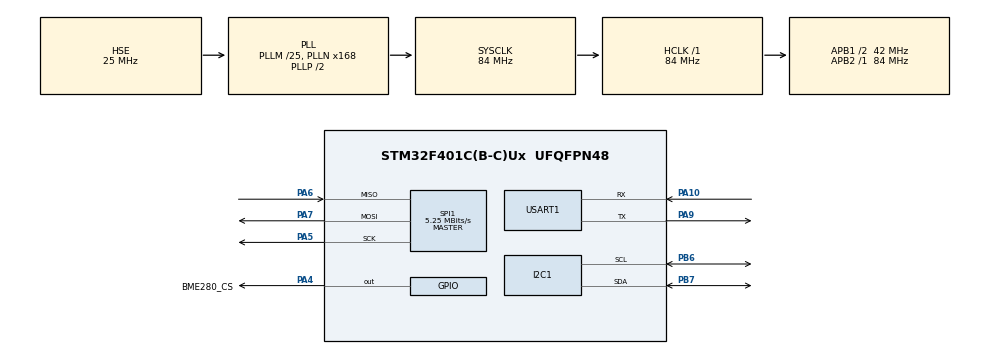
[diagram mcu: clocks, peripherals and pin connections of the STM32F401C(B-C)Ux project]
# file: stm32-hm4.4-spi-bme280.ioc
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FREERTOS.Tasks01=defaultTask,24,128,StartDefaultTask,Default,NULL,Dynamic,NULL,NULL
FREERTOS.configUSE_NEWLIB_REENTRANT=1
I2C1.I2C_Mode=I2C_Fast
Mcu.Family=STM32F4
Mcu.Name=STM32F401C(B-C)Ux
Mcu.Package=UFQFPN48
NVIC.PriorityGroup=NVIC_PRIORITYGROUP_4
NVIC.TIM1_UP_TIM10_IRQn=true\:15\:0\:false\:false\:true\:false\:false\:true\:true
NVIC.TimeBase=TIM1_UP_TIM10_IRQn
NVIC.TimeBaseIP=TIM1
PA10.Mode=Asynchronous
PA10.Signal=USART1_RX
PA13.Mode=Serial_Wire
PA13.Signal=SYS_JTMS-SWDIO
PA14.Mode=Serial_Wire
PA14.Signal=SYS_JTCK-SWCLK
PA4.GPIO_Label=BME280_CS
PA4.Signal=GPIO_Output
PA5.Mode=Full_Duplex_Master
PA5.Signal=SPI1_SCK
PA6.Mode=Full_Duplex_Master
PA6.Signal=SPI1_MISO
PA7.Mode=Full_Duplex_Master
PA7.Signal=SPI1_MOSI
PA9.Mode=Asynchronous
PA9.Signal=USART1_TX
PB6.Mode=I2C
PB6.Signal=I2C1_SCL
PB7.Mode=I2C
PB7.Signal=I2C1_SDA
PH0\ -\ OSC_IN.Mode=HSE-External-Oscillator
PH0\ -\ OSC_IN.Signal=RCC_OSC_IN
PH1\ -\ OSC_OUT.Mode=HSE-External-Oscillator
PH1\ -\ OSC_OUT.Signal=RCC_OSC_OUT
ProjectManager.HeapSize=0x200
ProjectManager.StackSize=0x400
ProjectManager.TargetToolchain=STM32CubeIDE
RCC.48MHZClocksFreq_Value=42000000
RCC.AHBFreq_Value=84000000
RCC.APB1CLKDivider=RCC_HCLK_DIV2
RCC.APB1Freq_Value=42000000
RCC.APB1TimFreq_Value=84000000
RCC.APB2Freq_Value=84000000
RCC.APB2TimFreq_Value=84000000
RCC.CortexFreq_Value=84000000
RCC.HCLKFreq_Value=84000000
RCC.HSE_VALUE=25000000
RCC.HSI_VALUE=16000000
RCC.LSE_VALUE=32768
RCC.PLLM=25
RCC.PLLN=168
RCC.PLLSourceVirtual=RCC_PLLSOURCE_HSE
RCC.SYSCLKFreq_VALUE=84000000
RCC.SYSCLKSource=RCC_SYSCLKSOURCE_PLLCLK
RCC.VCOOutputFreq_Value=168000000
SPI1.BaudRatePrescaler=SPI_BAUDRATEPRESCALER_16
SPI1.CalculateBaudRate=5.25 MBits/s
SPI1.Direction=SPI_DIRECTION_2LINES
SPI1.Mode=SPI_MODE_MASTER
SPI1.VirtualType=VM_MASTER
USART1.VirtualMode=VM_ASYNC
VP_FREERTOS_VS_CMSIS_V2.Mode=CMSIS_V2
VP_SYS_VS_tim1.Mode=TIM1
board=custom

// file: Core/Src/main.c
/* USER CODE BEGIN Header */
/**
  ******************************************************************************
  * @file           : main.c
  * @brief          : Main program body
  ******************************************************************************
  * @attention
  *
  * Copyright (c) 2026 STMicroelectronics.
  * All rights reserved.
  *
  * This software is licensed under terms that can be found in the LICENSE file
  * in the root directory of this software component.
  * If no LICENSE file comes with this software, it is provided AS-IS.
  *
  ******************************************************************************
  */
/* USER CODE END Header */
#include "main.h"
#include "cmsis_os.h"

/* USER CODE BEGIN Includes */
#include "app_main.h"
/* USER CODE END Includes */

I2C_HandleTypeDef hi2c1;

SPI_HandleTypeDef hspi1;

UART_HandleTypeDef huart1;

/* Definitions for defaultTask */
osThreadId_t defaultTaskHandle;
const osThreadAttr_t defaultTask_attributes = {
  .name = "defaultTask",
  .stack_size = 128 * 4,
  .priority = (osPriority_t) osPriorityNormal,
};

void SystemClock_Config(void);
static void MX_GPIO_Init(void);
static void MX_I2C1_Init(void);
static void MX_SPI1_Init(void);
static void MX_USART1_UART_Init(void);
void StartDefaultTask(void *argument);

/* USER CODE BEGIN 0 */
int __io_putchar(int ch) {
    HAL_UART_Transmit(&huart1, (uint8_t *)&ch, 1, 0xFFFF);
    return ch;
}
/* USER CODE END 0 */

int main(void)
{

  /* MCU Configuration--------------------------------------------------------*/

  /* Reset of all peripherals, Initializes the Flash interface and the Systick. */
  HAL_Init();

  /* Configure the system clock */
  SystemClock_Config();

  /* Initialize all configured peripherals */
  MX_GPIO_Init();
  MX_I2C1_Init();
  MX_SPI1_Init();
  MX_USART1_UART_Init();
  /* USER CODE BEGIN 2 */

  app_setup();

  /* USER CODE END 2 */

  /* Init scheduler */
  osKernelInitialize();

  /* Create the thread(s) */
  /* creation of defaultTask */
  defaultTaskHandle = osThreadNew(StartDefaultTask, NULL, &defaultTask_attributes);

  /* Start scheduler */
  osKernelStart();

  /* We should never get here as control is now taken by the scheduler */

  /* Infinite loop */
  while (1)
  {

  }
}

void SystemClock_Config(void)
{
  RCC_OscInitTypeDef RCC_OscInitStruct = {0};
  RCC_ClkInitTypeDef RCC_ClkInitStruct = {0};

  /** Configure the main internal regulator output voltage
  */
  __HAL_RCC_PWR_CLK_ENABLE();
  __HAL_PWR_VOLTAGESCALING_CONFIG(PWR_REGULATOR_VOLTAGE_SCALE2);

  /** Initializes the RCC Oscillators according to the specified parameters
  * in the RCC_OscInitTypeDef structure.
  */
  RCC_OscInitStruct.OscillatorType = RCC_OSCILLATORTYPE_HSE;
  RCC_OscInitStruct.HSEState = RCC_HSE_ON;
  RCC_OscInitStruct.PLL.PLLState = RCC_PLL_ON;
  RCC_OscInitStruct.PLL.PLLSource = RCC_PLLSOURCE_HSE;
  RCC_OscInitStruct.PLL.PLLM = 25;
  RCC_OscInitStruct.PLL.PLLN = 168;
  RCC_OscInitStruct.PLL.PLLP = RCC_PLLP_DIV2;
  RCC_OscInitStruct.PLL.PLLQ = 4;
  if (HAL_RCC_OscConfig(&RCC_OscInitStruct) != HAL_OK)
  {
    Error_Handler();
  }

  /** Initializes the CPU, AHB and APB buses clocks
  */
  RCC_ClkInitStruct.ClockType = RCC_CLOCKTYPE_HCLK|RCC_CLOCKTYPE_SYSCLK
                              |RCC_CLOCKTYPE_PCLK1|RCC_CLOCKTYPE_PCLK2;
  RCC_ClkInitStruct.SYSCLKSource = RCC_SYSCLKSOURCE_PLLCLK;
  RCC_ClkInitStruct.AHBCLKDivider = RCC_SYSCLK_DIV1;
  RCC_ClkInitStruct.APB1CLKDivider = RCC_HCLK_DIV2;
  RCC_ClkInitStruct.APB2CLKDivider = RCC_HCLK_DIV1;

  if (HAL_RCC_ClockConfig(&RCC_ClkInitStruct, FLASH_LATENCY_2) != HAL_OK)
  {
    Error_Handler();
  }
}

static void MX_I2C1_Init(void)
{

  hi2c1.Instance = I2C1;
  hi2c1.Init.ClockSpeed = 400000;
  hi2c1.Init.DutyCycle = I2C_DUTYCYCLE_2;
  hi2c1.Init.OwnAddress1 = 0;
  hi2c1.Init.AddressingMode = I2C_ADDRESSINGMODE_7BIT;
  hi2c1.Init.DualAddressMode = I2C_DUALADDRESS_DISABLE;
  hi2c1.Init.OwnAddress2 = 0;
  hi2c1.Init.GeneralCallMode = I2C_GENERALCALL_DISABLE;
  hi2c1.Init.NoStretchMode = I2C_NOSTRETCH_DISABLE;
  if (HAL_I2C_Init(&hi2c1) != HAL_OK)
  {
    Error_Handler();
  }

}

static void MX_SPI1_Init(void)
{

  /* SPI1 parameter configuration*/
  hspi1.Instance = SPI1;
  hspi1.Init.Mode = SPI_MODE_MASTER;
  hspi1.Init.Direction = SPI_DIRECTION_2LINES;
  hspi1.Init.DataSize = SPI_DATASIZE_8BIT;
  hspi1.Init.CLKPolarity = SPI_POLARITY_LOW;
  hspi1.Init.CLKPhase = SPI_PHASE_1EDGE;
  hspi1.Init.NSS = SPI_NSS_SOFT;
  hspi1.Init.BaudRatePrescaler = SPI_BAUDRATEPRESCALER_16;
  hspi1.Init.FirstBit = SPI_FIRSTBIT_MSB;
  hspi1.Init.TIMode = SPI_TIMODE_DISABLE;
  hspi1.Init.CRCCalculation = SPI_CRCCALCULATION_DISABLE;
  hspi1.Init.CRCPolynomial = 10;
  if (HAL_SPI_Init(&hspi1) != HAL_OK)
  {
    Error_Handler();
  }

}

static void MX_USART1_UART_Init(void)
{

  huart1.Instance = USART1;
  huart1.Init.BaudRate = 115200;
  huart1.Init.WordLength = UART_WORDLENGTH_8B;
  huart1.Init.StopBits = UART_STOPBITS_1;
  huart1.Init.Parity = UART_PARITY_NONE;
  huart1.Init.Mode = UART_MODE_TX_RX;
  huart1.Init.HwFlowCtl = UART_HWCONTROL_NONE;
  huart1.Init.OverSampling = UART_OVERSAMPLING_16;
  if (HAL_UART_Init(&huart1) != HAL_OK)
  {
    Error_Handler();
  }

}

static void MX_GPIO_Init(void)
{
  GPIO_InitTypeDef GPIO_InitStruct = {0};

  /* GPIO Ports Clock Enable */
  __HAL_RCC_GPIOH_CLK_ENABLE();
  __HAL_RCC_GPIOA_CLK_ENABLE();
  __HAL_RCC_GPIOB_CLK_ENABLE();

  /*Configure GPIO pin Output Level */
  HAL_GPIO_WritePin(BME280_CS_GPIO_Port, BME280_CS_Pin, GPIO_PIN_RESET);

  /*Configure GPIO pin : BME280_CS_Pin */
  GPIO_InitStruct.Pin = BME280_CS_Pin;
  GPIO_InitStruct.Mode = GPIO_MODE_OUTPUT_PP;
  GPIO_InitStruct.Pull = GPIO_NOPULL;
  GPIO_InitStruct.Speed = GPIO_SPEED_FREQ_LOW;
  HAL_GPIO_Init(BME280_CS_GPIO_Port, &GPIO_InitStruct);

}

void StartDefaultTask(void *argument)
{
  /* USER CODE BEGIN 5 */
    app_start();
    while(1) {
        app_loop();
    }
    /* USER CODE END 5 */
}

void HAL_TIM_PeriodElapsedCallback(TIM_HandleTypeDef *htim)
{
  if (htim->Instance == TIM1)
  {
    HAL_IncTick();
  }
}

void Error_Handler(void)
{
  __disable_irq();
  while (1)
  {
  }
}
